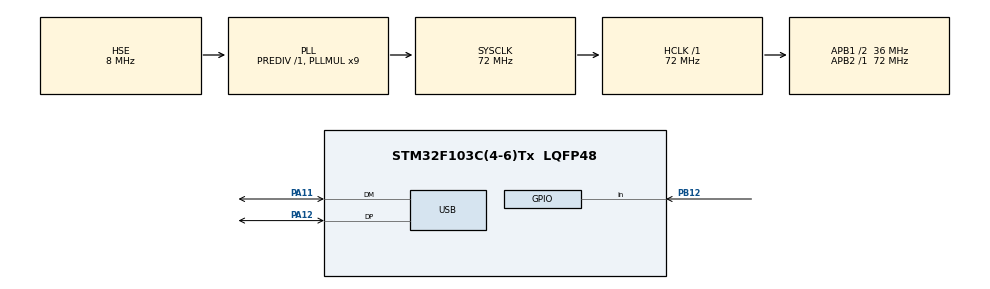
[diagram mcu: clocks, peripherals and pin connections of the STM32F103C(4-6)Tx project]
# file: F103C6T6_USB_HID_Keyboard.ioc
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Mcu.Family=STM32F1
Mcu.Name=STM32F103C(4-6)Tx
Mcu.Package=LQFP48
NVIC.PriorityGroup=NVIC_PRIORITYGROUP_4
NVIC.USB_LP_CAN1_RX0_IRQn=true\:0\:0\:false\:false\:true\:false\:true\:true
PA11.Mode=Device
PA11.Signal=USB_DM
PA12.Mode=Device
PA12.Signal=USB_DP
PA13.Mode=Serial_Wire
PA13.Signal=SYS_JTMS-SWDIO
PA14.Mode=Serial_Wire
PA14.Signal=SYS_JTCK-SWCLK
PB12.Signal=GPIO_Input
PD0-OSC_IN.Mode=HSE-External-Oscillator
PD0-OSC_IN.Signal=RCC_OSC_IN
PD1-OSC_OUT.Mode=HSE-External-Oscillator
PD1-OSC_OUT.Signal=RCC_OSC_OUT
ProjectManager.HeapSize=0x200
ProjectManager.StackSize=0x400
ProjectManager.TargetToolchain=STM32CubeIDE
RCC.AHBFreq_Value=72000000
RCC.APB1CLKDivider=RCC_HCLK_DIV2
RCC.APB1Freq_Value=36000000
RCC.APB1TimFreq_Value=72000000
RCC.APB2Freq_Value=72000000
RCC.APB2TimFreq_Value=72000000
RCC.HCLKFreq_Value=72000000
RCC.PLLMUL=RCC_PLL_MUL9
RCC.SYSCLKFreq_VALUE=72000000
RCC.SYSCLKSource=RCC_SYSCLKSOURCE_PLLCLK
RCC.USBFreq_Value=48000000
RCC.USBPrescaler=RCC_USBCLKSOURCE_PLL_DIV1_5
USB_DEVICE.CLASS_NAME_FS=HID
USB_DEVICE.PRODUCT_STRING_HID_FS=LT Password Keyboard
USB_DEVICE.VirtualMode=Hid
USB_DEVICE.VirtualModeFS=Hid_FS
VP_USB_DEVICE_VS_USB_DEVICE_HID_FS.Mode=HID_FS
board=custom

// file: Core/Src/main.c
/* USER CODE BEGIN Header */
/**
  ******************************************************************************
  * @file           : main.c
  * @brief          : Main program body
  ******************************************************************************
  * @attention
  *
  * Copyright (c) 2023 STMicroelectronics.
  * All rights reserved.
  *
  * This software is licensed under terms that can be found in the LICENSE file
  * in the root directory of this software component.
  * If no LICENSE file comes with this software, it is provided AS-IS.
  *
  ******************************************************************************
  */
/* USER CODE END Header */
#include "main.h"
#include "usb_device.h"

/* USER CODE BEGIN Includes */
#include "usbd_hid.h"
#include "usb_hid_keys.h"
/* USER CODE END Includes */

void SystemClock_Config(void);
static void MX_GPIO_Init(void);

/* USER CODE BEGIN 0 */
extern USBD_HandleTypeDef hUsbDeviceFS;

typedef struct
{
	uint8_t MODIFIER;
	uint8_t RESERVED;
	uint8_t KEYCODE1;
	uint8_t KEYCODE2;
	uint8_t KEYCODE3;
	uint8_t KEYCODE4;
	uint8_t KEYCODE5;
	uint8_t KEYCODE6;
} keyboardHID;

keyboardHID keyboardhid = {0,0,0,0,0,0,0,0};

int buttonPressed = 0; // Temporary for debugging

// Got from https://gist.github.com/MightyPork/6da26e382a7ad91b5496ee55fdc73db2
const char ascii_to_hid_key_map[95][2] = {
    {0, KEY_SPACE}, {KEY_MOD_LSHIFT, KEY_1}, {KEY_MOD_LSHIFT, KEY_APOSTROPHE},
    {KEY_MOD_LSHIFT, KEY_3}, {KEY_MOD_LSHIFT, KEY_4}, {KEY_MOD_LSHIFT, KEY_5},
    {KEY_MOD_LSHIFT, KEY_7}, {0, KEY_APOSTROPHE}, {KEY_MOD_LSHIFT, KEY_9},
    {KEY_MOD_LSHIFT, KEY_0}, {KEY_MOD_LSHIFT, KEY_8}, {KEY_MOD_LSHIFT, KEY_EQUAL},
    {0, KEY_COMMA}, {0, KEY_MINUS}, {0, KEY_DOT}, {0, KEY_SLASH}, {0, KEY_0},
    {0, KEY_1}, {0, KEY_2}, {0, KEY_3}, {0, KEY_4}, {0, KEY_5}, {0, KEY_6},
    {0, KEY_7}, {0, KEY_8}, {0, KEY_9}, {KEY_MOD_LSHIFT, KEY_SEMICOLON},
    {0, KEY_SEMICOLON}, {KEY_MOD_LSHIFT, KEY_COMMA}, {0, KEY_EQUAL},
    {KEY_MOD_LSHIFT, KEY_DOT}, {KEY_MOD_LSHIFT, KEY_SLASH}, {KEY_MOD_LSHIFT, KEY_2},
    {KEY_MOD_LSHIFT, KEY_A}, {KEY_MOD_LSHIFT, KEY_B}, {KEY_MOD_LSHIFT, KEY_C},
    {KEY_MOD_LSHIFT, KEY_D}, {KEY_MOD_LSHIFT, KEY_E}, {KEY_MOD_LSHIFT, KEY_F},
    {KEY_MOD_LSHIFT, KEY_G}, {KEY_MOD_LSHIFT, KEY_H}, {KEY_MOD_LSHIFT, KEY_I},
    {KEY_MOD_LSHIFT, KEY_J}, {KEY_MOD_LSHIFT, KEY_K}, {KEY_MOD_LSHIFT, KEY_L},
    {KEY_MOD_LSHIFT, KEY_M}, {KEY_MOD_LSHIFT, KEY_N}, {KEY_MOD_LSHIFT, KEY_O},
    {KEY_MOD_LSHIFT, KEY_P}, {KEY_MOD_LSHIFT, KEY_Q}, {KEY_MOD_LSHIFT, KEY_R},
    {KEY_MOD_LSHIFT, KEY_S}, {KEY_MOD_LSHIFT, KEY_T}, {KEY_MOD_LSHIFT, KEY_U},
    {KEY_MOD_LSHIFT, KEY_V}, {KEY_MOD_LSHIFT, KEY_W}, {KEY_MOD_LSHIFT, KEY_X},
    {KEY_MOD_LSHIFT, KEY_Y}, {KEY_MOD_LSHIFT, KEY_Z}, {0, KEY_LEFTBRACE},
    {0, KEY_BACKSLASH}, {0, KEY_RIGHTBRACE}, {KEY_MOD_LSHIFT, KEY_6},
    {KEY_MOD_LSHIFT, KEY_MINUS}, {0, KEY_GRAVE}, {0, KEY_A}, {0, KEY_B},
    {0, KEY_C}, {0, KEY_D}, {0, KEY_E}, {0, KEY_F}, {0, KEY_G}, {0, KEY_H},
    {0, KEY_I}, {0, KEY_J}, {0, KEY_K}, {0, KEY_L}, {0, KEY_M}, {0, KEY_N},
    {0, KEY_O}, {0, KEY_P}, {0, KEY_Q}, {0, KEY_R}, {0, KEY_S}, {0, KEY_T},
    {0, KEY_U}, {0, KEY_V}, {0, KEY_W}, {0, KEY_X}, {0, KEY_Y}, {0, KEY_Z},
    {KEY_MOD_LSHIFT, KEY_LEFTBRACE}, {KEY_MOD_LSHIFT, KEY_BACKSLASH},
    {KEY_MOD_LSHIFT, KEY_RIGHTBRACE}, {KEY_MOD_LSHIFT, KEY_GRAVE},
};

typedef struct
{
	uint8_t MODIFIER;
	uint8_t KEYCODE1;
} charKeyboardHID;

#define MAX_PASSWORD_LEN 64

uint8_t passwordLen;
charKeyboardHID passwordKeypress[MAX_PASSWORD_LEN];

// Convert a character into a modifier and key
charKeyboardHID encodeChar(char c) {
	charKeyboardHID kp = { 0, 0 };

	if (c < 32 || c > 127)
		return kp; // Error

	int ch = c - 32;
	kp.MODIFIER = ascii_to_hid_key_map[ch][0];
	kp.KEYCODE1 = ascii_to_hid_key_map[ch][1];
	return kp;
}
/* USER CODE END 0 */

int main(void)
{

  /* MCU Configuration--------------------------------------------------------*/

  /* Reset of all peripherals, Initializes the Flash interface and the Systick. */
  HAL_Init();

  /* Configure the system clock */
  SystemClock_Config();

  /* Initialize all configured peripherals */
  MX_GPIO_Init();
  MX_USB_DEVICE_Init();
  /* USER CODE BEGIN 2 */
  const char *password = "AbC123456!@#$%^,./;"; // Testing a variety of characters

  passwordLen = strlen(password);

  for(int i = 0; i < passwordLen; i++) {
	  passwordKeypress[i] = encodeChar(password[i]);
  }
  /* USER CODE END 2 */

  /* Infinite loop */
  while (1)
  {

    /* USER CODE BEGIN 3 */
	  buttonPressed = 0;

	  if (HAL_GPIO_ReadPin(GPIOB, GPIO_PIN_12) == GPIO_PIN_SET) {
		  buttonPressed = 1;

		  for(int i = 0; i < passwordLen; i++) {
			  // Send the i-th character

			  keyboardhid.MODIFIER = passwordKeypress[i].MODIFIER;
			  keyboardhid.KEYCODE1 = passwordKeypress[i].KEYCODE1;
			  USBD_HID_SendReport(&hUsbDeviceFS, (uint8_t*)&keyboardhid, sizeof (keyboardhid));

			  HAL_Delay (50);

			  keyboardhid.MODIFIER = 0x00;
			  keyboardhid.KEYCODE1 = 0x00;
			  USBD_HID_SendReport(&hUsbDeviceFS, (uint8_t*)&keyboardhid, sizeof (keyboardhid));

			  HAL_Delay (50);
		  }
	  }

	  // This is bad approach: the button press is only detected twice in a second.
	  // User has to hold and release it in time.
	  HAL_Delay(500);
  }
  /* USER CODE END 3 */
}

void SystemClock_Config(void)
{
  RCC_OscInitTypeDef RCC_OscInitStruct = {0};
  RCC_ClkInitTypeDef RCC_ClkInitStruct = {0};
  RCC_PeriphCLKInitTypeDef PeriphClkInit = {0};

  /** Initializes the RCC Oscillators according to the specified parameters
  * in the RCC_OscInitTypeDef structure.
  */
  RCC_OscInitStruct.OscillatorType = RCC_OSCILLATORTYPE_HSE;
  RCC_OscInitStruct.HSEState = RCC_HSE_ON;
  RCC_OscInitStruct.HSEPredivValue = RCC_HSE_PREDIV_DIV1;
  RCC_OscInitStruct.HSIState = RCC_HSI_ON;
  RCC_OscInitStruct.PLL.PLLState = RCC_PLL_ON;
  RCC_OscInitStruct.PLL.PLLSource = RCC_PLLSOURCE_HSE;
  RCC_OscInitStruct.PLL.PLLMUL = RCC_PLL_MUL9;
  if (HAL_RCC_OscConfig(&RCC_OscInitStruct) != HAL_OK)
  {
    Error_Handler();
  }

  /** Initializes the CPU, AHB and APB buses clocks
  */
  RCC_ClkInitStruct.ClockType = RCC_CLOCKTYPE_HCLK|RCC_CLOCKTYPE_SYSCLK
                              |RCC_CLOCKTYPE_PCLK1|RCC_CLOCKTYPE_PCLK2;
  RCC_ClkInitStruct.SYSCLKSource = RCC_SYSCLKSOURCE_PLLCLK;
  RCC_ClkInitStruct.AHBCLKDivider = RCC_SYSCLK_DIV1;
  RCC_ClkInitStruct.APB1CLKDivider = RCC_HCLK_DIV2;
  RCC_ClkInitStruct.APB2CLKDivider = RCC_HCLK_DIV1;

  if (HAL_RCC_ClockConfig(&RCC_ClkInitStruct, FLASH_LATENCY_2) != HAL_OK)
  {
    Error_Handler();
  }
  PeriphClkInit.PeriphClockSelection = RCC_PERIPHCLK_USB;
  PeriphClkInit.UsbClockSelection = RCC_USBCLKSOURCE_PLL_DIV1_5;
  if (HAL_RCCEx_PeriphCLKConfig(&PeriphClkInit) != HAL_OK)
  {
    Error_Handler();
  }
}

static void MX_GPIO_Init(void)
{
  GPIO_InitTypeDef GPIO_InitStruct = {0};

  /* GPIO Ports Clock Enable */
  __HAL_RCC_GPIOD_CLK_ENABLE();
  __HAL_RCC_GPIOB_CLK_ENABLE();
  __HAL_RCC_GPIOA_CLK_ENABLE();

  /*Configure GPIO pin : PB12 */
  GPIO_InitStruct.Pin = GPIO_PIN_12;
  GPIO_InitStruct.Mode = GPIO_MODE_INPUT;
  GPIO_InitStruct.Pull = GPIO_NOPULL;
  HAL_GPIO_Init(GPIOB, &GPIO_InitStruct);

}

void Error_Handler(void)
{
  __disable_irq();
  while (1)
  {
  }
}
